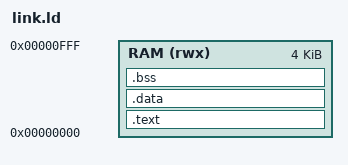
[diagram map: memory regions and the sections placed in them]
ENTRY(main)

MEMORY
{
    RAM (rwx) : ORIGIN = 0x00000000, LENGTH = 4K
}

SECTIONS
{
    .text :
    {
        *(.text*)
        *(.rodata*)
    } > RAM

    .data :
    {
        *(.data*)
    } > RAM

    .bss :
    {
        *(.bss*)
    } > RAM
}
